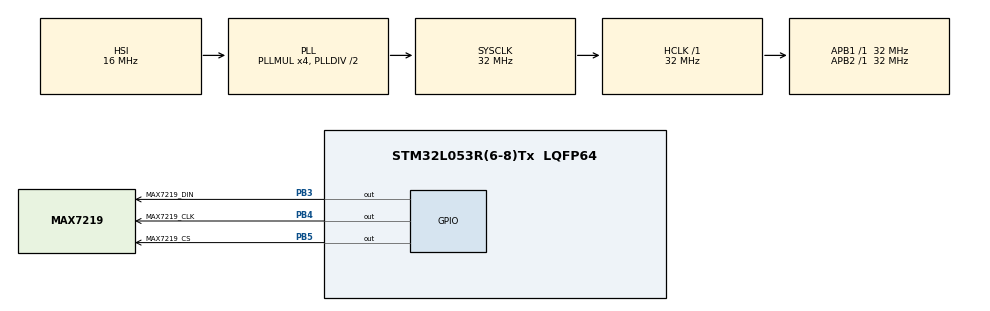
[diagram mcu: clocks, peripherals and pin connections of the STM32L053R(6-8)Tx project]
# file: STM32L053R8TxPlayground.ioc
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Mcu.Family=STM32L0
Mcu.Name=STM32L053R(6-8)Tx
Mcu.Package=LQFP64
PB3.GPIO_Label=MAX7219_DIN
PB3.GPIO_Speed=GPIO_SPEED_FREQ_HIGH
PB3.Signal=GPIO_Output
PB4.GPIO_Label=MAX7219_CLK
PB4.GPIO_Speed=GPIO_SPEED_FREQ_HIGH
PB4.Signal=GPIO_Output
PB5.GPIO_Label=MAX7219_CS
PB5.GPIO_Speed=GPIO_SPEED_FREQ_HIGH
PB5.Signal=GPIO_Output
PH0-OSC_IN.Mode=HSE-External-Oscillator
PH0-OSC_IN.Signal=RCC_OSC_IN
PH1-OSC_OUT.Mode=HSE-External-Oscillator
PH1-OSC_OUT.Signal=RCC_OSC_OUT
ProjectManager.HeapSize=0x200
ProjectManager.StackSize=0x400
ProjectManager.TargetToolchain=MDK-ARM V5
RCC.AHBFreq_Value=32000000
RCC.APB1Freq_Value=32000000
RCC.APB1TimFreq_Value=32000000
RCC.APB2Freq_Value=32000000
RCC.APB2TimFreq_Value=32000000
RCC.HCLKFreq_Value=32000000
RCC.HSI16_VALUE=16000000
RCC.HSI48_VALUE=48000000
RCC.HSI_VALUE=16000000
RCC.LSE_VALUE=32768
RCC.MSI_VALUE=2097000
RCC.PLLMUL=RCC_PLLMUL_4
RCC.SYSCLKFreq_VALUE=32000000
RCC.SYSCLKSource=RCC_SYSCLKSOURCE_PLLCLK
RCC.VCOOutputFreq_Value=64000000
board=custom

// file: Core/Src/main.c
/* USER CODE BEGIN Header */
/**
  ******************************************************************************
  * @file           : main.c
  * @brief          : Main program body
  ******************************************************************************
  * @attention
  *
  * <h2><center>&copy; Copyright (c) 2021 STMicroelectronics.
  * All rights reserved.</center></h2>
  *
  * This software component is licensed by ST under BSD 3-Clause license,
  * the "License"; You may not use this file except in compliance with the
  * License. You may obtain a copy of the License at:
  *                        opensource.org/licenses/BSD-3-Clause
  *
  ******************************************************************************
  */
/* USER CODE END Header */
#include "main.h"

/* USER CODE BEGIN Includes */
#include "max7219.h"

/* USER CODE END Includes */

void SystemClock_Config(void);
static void MX_GPIO_Init(void);

/* USER CODE BEGIN 0 */
const uint8_t data[10][8] =
{
	{0x00, 0x3c, 0x24, 0x24, 0x24, 0x24, 0x3c, 0x00},//0
	{0x00, 0x18, 0x1c, 0x18, 0x18, 0x18, 0x3c, 0x00},//1
	{0x00, 0x3c, 0x20, 0x30, 0x0c, 0x04, 0x3c, 0x00},//2
	{0x00, 0x3c, 0x20, 0x20, 0x3c, 0x20, 0x3c, 0x00},//3
	{0x00, 0x24, 0x24, 0x24, 0x3c, 0x20, 0x20, 0x00},//4
	{0x00, 0x3c, 0x04, 0x04, 0x3c, 0x20, 0x3c, 0x00},//5
	{0x00, 0x3c, 0x04, 0x04, 0x3c, 0x24, 0x3c, 0x00},//6
	{0x00, 0x3c, 0x20, 0x20, 0x20, 0x20, 0x20, 0x00},//7
	{0x00, 0x3c, 0x24, 0x24, 0x3c, 0x24, 0x3c, 0x00},//8
	{0x00, 0x3c, 0x24, 0x24, 0x3c, 0x20, 0x20, 0x00}//9
};

/* USER CODE END 0 */

int main(void)
{

  /* MCU Configuration--------------------------------------------------------*/

  /* Reset of all peripherals, Initializes the Flash interface and the Systick. */
  HAL_Init();

  /* Configure the system clock */
  SystemClock_Config();

  /* Initialize all configured peripherals */
  MX_GPIO_Init();
  /* USER CODE BEGIN 2 */

	setDinPin(MAX7219_DIN_GPIO_Port,MAX7219_DIN_Pin);
	setCSPin(MAX7219_CS_GPIO_Port,MAX7219_CS_Pin);
	setCLKPin(MAX7219_CLK_GPIO_Port,MAX7219_CLK_Pin);

	MAX7219_Init();
  /* USER CODE END 2 */

  /* Infinite loop */
  while (1)
  {

		for(uint8_t num=0;num<10;num++){
			for(uint8_t i=0;i<8;i++){
				setDigit(0,i,data[num][7-i]);
			}
			HAL_Delay(1000);
			clear();

		}

  }
}

void SystemClock_Config(void)
{
  RCC_OscInitTypeDef RCC_OscInitStruct = {0};
  RCC_ClkInitTypeDef RCC_ClkInitStruct = {0};

  /** Configure the main internal regulator output voltage
  */
  __HAL_PWR_VOLTAGESCALING_CONFIG(PWR_REGULATOR_VOLTAGE_SCALE1);
  /** Initializes the RCC Oscillators according to the specified parameters
  * in the RCC_OscInitTypeDef structure.
  */
  RCC_OscInitStruct.OscillatorType = RCC_OSCILLATORTYPE_HSI;
  RCC_OscInitStruct.HSIState = RCC_HSI_ON;
  RCC_OscInitStruct.HSICalibrationValue = RCC_HSICALIBRATION_DEFAULT;
  RCC_OscInitStruct.PLL.PLLState = RCC_PLL_ON;
  RCC_OscInitStruct.PLL.PLLSource = RCC_PLLSOURCE_HSI;
  RCC_OscInitStruct.PLL.PLLMUL = RCC_PLLMUL_4;
  RCC_OscInitStruct.PLL.PLLDIV = RCC_PLLDIV_2;
  if (HAL_RCC_OscConfig(&RCC_OscInitStruct) != HAL_OK)
  {
    Error_Handler();
  }
  /** Initializes the CPU, AHB and APB buses clocks
  */
  RCC_ClkInitStruct.ClockType = RCC_CLOCKTYPE_HCLK|RCC_CLOCKTYPE_SYSCLK
                              |RCC_CLOCKTYPE_PCLK1|RCC_CLOCKTYPE_PCLK2;
  RCC_ClkInitStruct.SYSCLKSource = RCC_SYSCLKSOURCE_PLLCLK;
  RCC_ClkInitStruct.AHBCLKDivider = RCC_SYSCLK_DIV1;
  RCC_ClkInitStruct.APB1CLKDivider = RCC_HCLK_DIV1;
  RCC_ClkInitStruct.APB2CLKDivider = RCC_HCLK_DIV1;

  if (HAL_RCC_ClockConfig(&RCC_ClkInitStruct, FLASH_LATENCY_1) != HAL_OK)
  {
    Error_Handler();
  }
}

static void MX_GPIO_Init(void)
{
  GPIO_InitTypeDef GPIO_InitStruct = {0};

  /* GPIO Ports Clock Enable */
  __HAL_RCC_GPIOH_CLK_ENABLE();
  __HAL_RCC_GPIOB_CLK_ENABLE();

  /*Configure GPIO pin Output Level */
  HAL_GPIO_WritePin(GPIOB, MAX7219_DIN_Pin|MAX7219_CLK_Pin|MAX7219_CS_Pin, GPIO_PIN_RESET);

  /*Configure GPIO pins : MAX7219_DIN_Pin MAX7219_CLK_Pin MAX7219_CS_Pin */
  GPIO_InitStruct.Pin = MAX7219_DIN_Pin|MAX7219_CLK_Pin|MAX7219_CS_Pin;
  GPIO_InitStruct.Mode = GPIO_MODE_OUTPUT_PP;
  GPIO_InitStruct.Pull = GPIO_NOPULL;
  GPIO_InitStruct.Speed = GPIO_SPEED_FREQ_HIGH;
  HAL_GPIO_Init(GPIOB, &GPIO_InitStruct);

}

void Error_Handler(void)
{
  __disable_irq();
  while (1)
  {
  }
}

/************************ (C) COPYRIGHT STMicroelectronics *****END OF FILE****/
